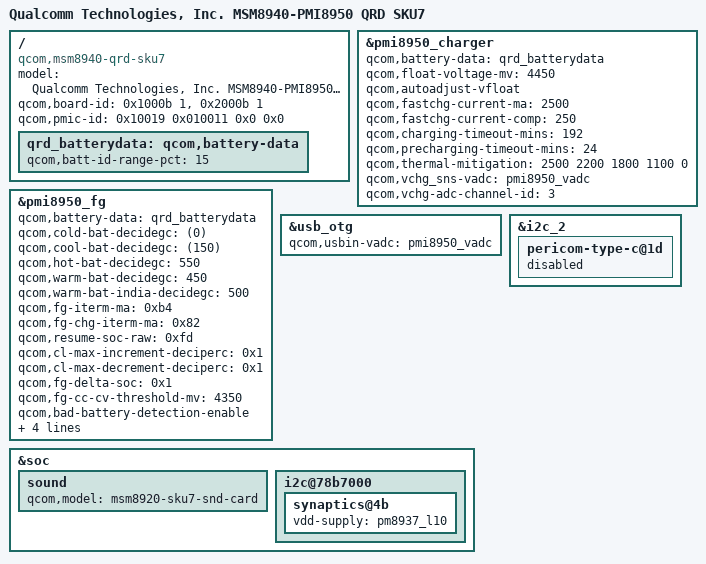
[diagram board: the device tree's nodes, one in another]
/*
 * Copyright (c) 2018, The Linux Foundation. All rights reserved.
 *
 * This program is free software; you can redistribute it and/or modify
 * it under the terms of the GNU General Public License version 2 and
 * only version 2 as published by the Free Software Foundation.
 *
 * This program is distributed in the hope that it will be useful,
 * but WITHOUT ANY WARRANTY; without even the implied warranty of
 * MERCHANTABILITY or FITNESS FOR A PARTICULAR PURPOSE.  See the
 * GNU General Public License for more details.
 */

/dts-v1/;

#include "msm8940.dtsi"
#include "msm8937-pmi8950-qrd-sku1.dtsi"
#include "msm8940-camera-sensor-qrd.dtsi"
#include "msm8940-pinctrl.dtsi"

/ {
	model = "Qualcomm Technologies, Inc. MSM8940-PMI8950 QRD SKU7";
	compatible = "qcom,msm8940-qrd-sku7", "qcom,msm8940-qrd",
		   "qcom,msm8940", "qcom,qrd";
	qcom,board-id= <0x1000b 1>, <0x2000b 1>;
	qcom,pmic-id = <0x10019 0x010011 0x0 0x0>;
};

/ {
	qrd_batterydata: qcom,battery-data {
		qcom,batt-id-range-pct = <15>;
		#include "batterydata-qrd-Desay-4v4-4100mah.dtsi"
		#include "batterydata-qrd-Atl-4v4-4100mah.dtsi"
		#include "batterydata-qrd-Coslight-4v4-4100mah.dtsi"
		#include "batterydata-qrd-Default-4v4-4100mah.dtsi"
	};
};

&pmi8950_charger {
	qcom,battery-data = <&qrd_batterydata>;
	qcom,float-voltage-mv = <4450>;
	qcom,autoadjust-vfloat;
	qcom,fastchg-current-ma = <2500>;
	qcom,fastchg-current-comp = <250>;
	qcom,charging-timeout-mins = <192>;
	qcom,precharging-timeout-mins = <24>;
	qcom,thermal-mitigation = <2500 2200 1800 1100 0>;
	status = "okay";
	qcom,vchg_sns-vadc = <&pmi8950_vadc>;
	qcom,vchg-adc-channel-id = <3>;
};

&pmi8950_fg {
	qcom,battery-data = <&qrd_batterydata>;
	qcom,cold-bat-decidegc = <(0)>;
	qcom,cool-bat-decidegc = <(150)>;
	qcom,hot-bat-decidegc = <550>;
	qcom,warm-bat-decidegc = <450>;
	qcom,warm-bat-india-decidegc = <500>;
	qcom,fg-iterm-ma = <0xb4>;
	qcom,fg-chg-iterm-ma = <0x82>;
	qcom,resume-soc-raw = <0xfd>;	
	qcom,cl-max-increment-deciperc = <0x1>;
	qcom,cl-max-decrement-deciperc = <0x1>;
	qcom,fg-delta-soc = <0x1>;
	qcom,fg-cc-cv-threshold-mv = <4350>;
	qcom,bad-battery-detection-enable;
	qcom,capacity-estimation-on;
	qcom,esr-pulse-tuning-en;
	qcom,hold-soc-while-full;
	qcom,thermal-coefficients = [B7 85 B2 49 71 35];
};

&usb_otg {
	qcom,usbin-vadc = <&pmi8950_vadc>;
};

&soc {
	sound {
		qcom,model = "msm8920-sku7-snd-card";
	};

	i2c@78b7000 {
		synaptics@4b {
			vdd-supply = <&pm8937_l10>;
		};
	};
};

&i2c_2 {
	pericom-type-c@1d {
		status="disabled";
	};
};
